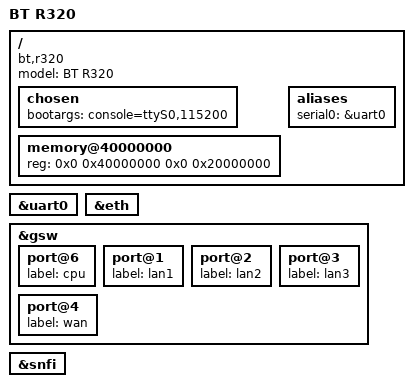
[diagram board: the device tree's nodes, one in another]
/dts-v1/;

#include "mt7981.dtsi"

/ {
	model = "BT R320";
	compatible = "bt,r320", "mediatek,mt7981";

	chosen {
		bootargs = "console=ttyS0,115200";
	};

	memory@40000000 {
		device_type = "memory";
		reg = <0x0 0x40000000 0x0 0x20000000>; /* 512MB，后面可改 */
	};

	aliases {
		serial0 = &uart0;
	};
};

&uart0 {
	status = "okay";
};

&eth {
	status = "okay";
};

&gsw {
	status = "okay";

	port@6 {
		status = "okay";
		label = "cpu";
	};

	port@1 { label = "lan1"; status = "okay"; };
	port@2 { label = "lan2"; status = "okay"; };
	port@3 { label = "lan3"; status = "okay"; };
	port@4 { label = "wan";  status = "okay"; };
};

&snfi {
	status = "okay";
};
